# PIC32MZ0512EFF144 device description
Architecture: 32xxxx; Family: PIC32MZEF; Series: PIC32MZ
Registers are 32-bit, read-write, no defined reset value unless marked. A register's access mark holds for its fields unless they carry their own. Offsets are from the block's base; [hi:lo] are bit positions; 'fields as' and 'values as' point back to an identical list.

## UART
Instances: UART 0x1f822000 in periph_pb2_std
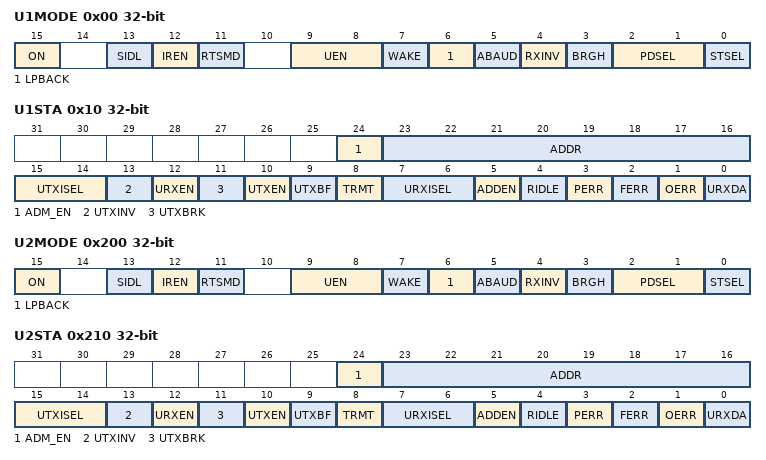
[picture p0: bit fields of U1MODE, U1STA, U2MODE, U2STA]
0x00 U1MODE — UARTx Mode Register
  [15] ON — UARTx Enable bit
    1=UARTx is enabled. UARTx pins are controlled by UARTx as defined by UEN and UTXEN control bits; 0=UARTx is disabled. All UARTx pins are controlled by corresponding bits in the PORTx
  [13] SIDL — Stop in Idle Mode bit
    1=Discontinue operation when device enters Idle mode; 0=Continue operation in Idle mode
  [12] IREN — IrDA Encoder and Decoder Enable bit
    1=IrDA is enabled; 0=IrDA is disabled
  [11] RTSMD — Mode Selection for UxRTS Pin bit
    1=UxRTS pin is in Simplex mode; 0=UxRTS pin is in Flow Control mode
  [9:8] UEN — UARTx Enable bits
    3=UxTX; 2=UxTX; 1=UxTX; 0=UxTX and UxRX pins are enabled and used; UxCTS and UxRTS/UxBCLK pins are controlled by corresponding bits in the PORTx register
  [7] WAKE — Enable Wake-up on Start bit Detect During Sleep Mode bit
    1=Wake-up is enabled; 0=Wake-up is disabled
  [6] LPBACK — UARTx Loopback Mode Select bit
    1=Loopback mode is enabled; 0=Loopback mode is disabled
  [5] ABAUD — Auto-Baud Enable bit
    1=Enable baud rate measurement on the next character requires reception of Sync character (0x55); cleared by hardware upon completion; 0=Baud rate measurement is disabled or completed
  [4] RXINV — Receive Polarity Inversion bit
    1=UxRX Idle state is 0; 0=UxRX Idle state is 1
  [3] BRGH — High Baud Rate Enable bit
    1=High-Speed mode 4x baud clock enabled; 0=Standard Speed mode 16x baud clock enabled
  [2:1] PDSEL — Parity and Data Selection bits
    3=9-bit data, no parity; 2=8-bit data, odd parity; 1=8-bit data, even parity; 0=8-bit data, no parity
  [0] STSEL — Stop Selection bit
    1=2 Stop bits; 0=1 Stop bit
0x10 U1STA — UARTx Status and Control Register
  [24] ADM_EN — Automatic Address Detect Mode Enable bit
    1=Automatic Address Detect mode is enabled; 0=Automatic Address Detect mode is disabled
  [23:16] ADDR
  [15:14] UTXISEL — TX Interrupt Mode Selection bits
    2=Interrupt is generated and asserted while the transmit buffer is empty; 1=Interrupt is generated and asserted when all characters have been transmitted; 0=Interrupt is generated and asserted while the transmit buffer contains at least one empty space
  [13] UTXINV — Transmit Polarity Inversion bit
    1=(If IrDA mode is disabled (i.e; 0=(If IrDA mode is disabled (i.e
  [12] URXEN — Receiver Enable bit
    1=UARTx receiver is enabled. UxRX pin is controlled by UARTx (if ON = 1); 0=UARTx receiver is disabled. UxRX pin is ignored by the UARTx module
  [11] UTXBRK — Transmit Break bit
    1=Send Break on next transmission. Start bit followed by twelve 0 bits; 0=Break transmission is disabled or completed
  [10] UTXEN — Transmit Enable bit
    1=UARTx transmitter is enabled. UxTX pin is controlled by UARTx (if ON = 1); 0=UARTx transmitter is disabled. Any pending transmission is aborted and buffer is reset
  [9] UTXBF — Transmit Buffer Full Status bit
    1=Transmit buffer is full; 0=Transmit buffer is not full
  [8] TRMT
  [7:6] URXISEL — Receive Interrupt Mode Selection bit
    2=Interrupt flag bit is asserted while receive buffer is 3/4 or more full; 1=Interrupt flag bit is asserted while receive buffer is 1/2 or more full; 0=Interrupt flag bit is asserted while receive buffer is not empty (i.e
  [5] ADDEN — Address Character Detect bit
    1=Address Detect mode is enabled. If 9-bit mode is not selected; 0=Address Detect mode is disabled
  [4] RIDLE — Receiver Idle bit
    1=Receiver is Idle; 0=Data is being received
  [3] PERR — Parity Error Status bit
    1=Parity error has been detected for the current character; 0=Parity error has not been detected
  [2] FERR — Framing Error Status bit
    1=Framing error has been detected for the current character; 0=Framing error has not been detected
  [1] OERR — Receive Buffer Overrun Error Status bit.
    1=Receive buffer has overflowed; 0=Receive buffer has not overflowed
  [0] URXDA — Receive Buffer Data Available bit
    1=Receive buffer has data, at least one more character can be read; 0=Receive buffer is empty
0x20 U1TXREG
  [8:0] U1TXREG
0x30 U1RXREG ro
  [8:0] U1RXREG
0x40 U1BRG
  [15:0] BRG
0x200 U2MODE — UARTx Mode Register
  [15] ON — UARTx Enable bit
    values as U1MODE.ON
  [13] SIDL — Stop in Idle Mode bit
    values as U1MODE.SIDL
  [12] IREN — IrDA Encoder and Decoder Enable bit
    1=IrDA is enabled; 0=IrDA is disabled
  [11] RTSMD — Mode Selection for UxRTS Pin bit
    values as U1MODE.RTSMD
  [9:8] UEN — UARTx Enable bits
    values as U1MODE.UEN
  [7] WAKE — Enable Wake-up on Start bit Detect During Sleep Mode bit
    1=Wake-up is enabled; 0=Wake-up is disabled
  [6] LPBACK — UARTx Loopback Mode Select bit
    1=Loopback mode is enabled; 0=Loopback mode is disabled
  [5] ABAUD — Auto-Baud Enable bit
    values as U1MODE.ABAUD
  [4] RXINV — Receive Polarity Inversion bit
    1=UxRX Idle state is 0; 0=UxRX Idle state is 1
  [3] BRGH — High Baud Rate Enable bit
    values as U1MODE.BRGH
  [2:1] PDSEL — Parity and Data Selection bits
    3=9-bit data; 2=8-bit data; 1=8-bit data; 0=8-bit data
  [0] STSEL — Stop Selection bit
    1=2 Stop bits; 0=1 Stop bit
0x210 U2STA — UARTx Status and Control Register
  [24] ADM_EN — Automatic Address Detect Mode Enable bit
    values as U1STA.ADM_EN
  [23:16] ADDR
  [15:14] UTXISEL — TX Interrupt Mode Selection bits
    values as U1STA.UTXISEL
  [13] UTXINV — Transmit Polarity Inversion bit
    values as U1STA.UTXINV
  [12] URXEN — Receiver Enable bit
    values as U1STA.URXEN
  [11] UTXBRK — Transmit Break bit
    values as U1STA.UTXBRK
  [10] UTXEN — Transmit Enable bit
    values as U1STA.UTXEN
  [9] UTXBF — Transmit Buffer Full Status bit
    1=Transmit buffer is full; 0=Transmit buffer is not full
  [8] TRMT
  [7:6] URXISEL — Receive Interrupt Mode Selection bit
    values as U1STA.URXISEL
  [5] ADDEN — Address Character Detect bit
    values as U1STA.ADDEN
  [4] RIDLE — Receiver Idle bit
    1=Receiver is Idle; 0=Data is being received
  [3] PERR — Parity Error Status bit
    values as U1STA.PERR
  [2] FERR — Framing Error Status bit
    values as U1STA.FERR
  [1] OERR — Receive Buffer Overrun Error Status bit.
    values as U1STA.OERR
  [0] URXDA
0x220 U2TXREG
  [8:0] U2TXREG
0x230 U2RXREG ro
  [8:0] U2RXREG
0x240 U2BRG
  [15:0] BRG
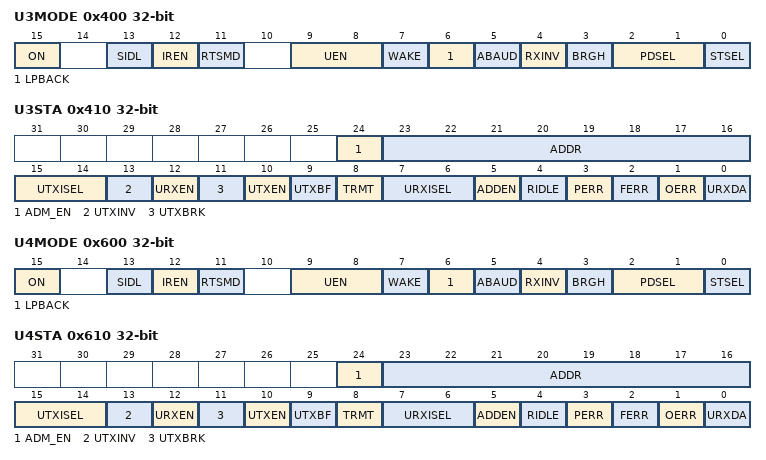
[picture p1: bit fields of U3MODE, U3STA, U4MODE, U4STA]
0x400 U3MODE — UARTx Mode Register
  fields as U2MODE
0x410 U3STA — UARTx Status and Control Register
  fields as U2STA
0x420 U3TXREG
  [8:0] U3TXREG
0x430 U3RXREG ro
  [8:0] U3RXREG
0x440 U3BRG
  [15:0] BRG
0x600 U4MODE — UARTx Mode Register
  fields as U2MODE
0x610 U4STA — UARTx Status and Control Register
  fields as U2STA
0x620 U4TXREG
  [8:0] U4TXREG
0x630 U4RXREG ro
  [8:0] U4RXREG
0x640 U4BRG
  [15:0] BRG
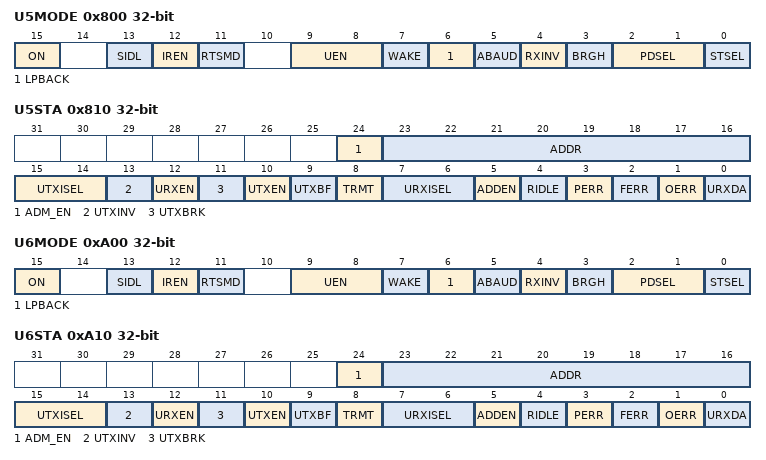
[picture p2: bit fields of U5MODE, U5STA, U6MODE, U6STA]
0x800 U5MODE — UARTx Mode Register
  fields as U2MODE
0x810 U5STA — UARTx Status and Control Register
  fields as U2STA
0x820 U5TXREG
  [8:0] U5TXREG
0x830 U5RXREG ro
  [8:0] U5RXREG
0x840 U5BRG
  [15:0] BRG
0xA00 U6MODE — UARTx Mode Register
  fields as U2MODE
0xA10 U6STA — UARTx Status and Control Register
  fields as U2STA
0xA20 U6TXREG
  [8:0] U6TXREG
0xA30 U6RXREG ro
  [8:0] U6RXREG
0xA40 U6BRG
  [15:0] BRG
